VERSION ""

NS_ :

BS_:

BU_:

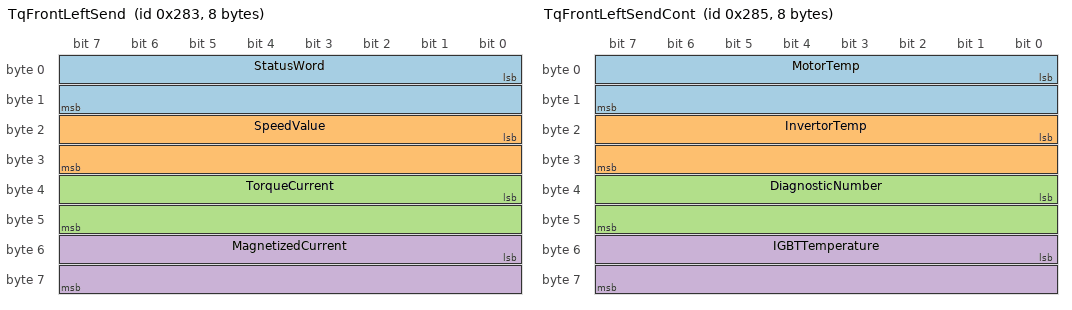
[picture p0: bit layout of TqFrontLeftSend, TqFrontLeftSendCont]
BO_ 643 TqFrontLeftSend: 8 Vector__XXX
 SG_ StatusWord : 0|16@1+ (1,0) [0|1] "Status Word" Vector__XXX
 SG_ SpeedValue : 16|16@1- (0.01,0) [0|5000] "1/rpm" Vector__XXX
 SG_ TorqueCurrent : 32|16@1- (0.01,0) [0|5000] "Iq" Vector__XXX
 SG_ MagnetizedCurrent : 48|16@1- (0.01,0) [0|5000] "Id" Vector__XXX

BO_ 645 TqFrontLeftSendCont: 8 Vector__XXX
 SG_ MotorTemp : 0|16@1- (0.1,0) [0|500] "C" Vector__XXX
 SG_ InvertorTemp : 16|16@1- (0.1,0) [0|500] "C" Vector__XXX
 SG_ DiagnosticNumber : 32|16@1+ (1,0) [0|20] "" Vector__XXX
 SG_ IGBTTemperature : 48|16@1- (0.1,0) [0|500] "C" Vector__XXX

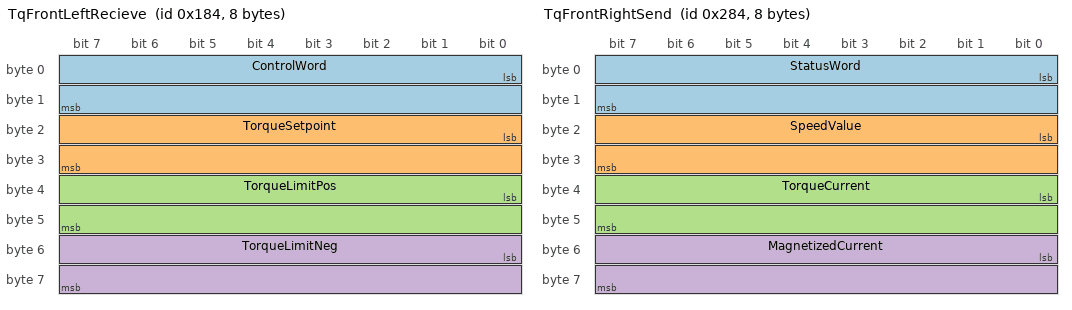
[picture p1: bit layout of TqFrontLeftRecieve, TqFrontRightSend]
BO_ 388 TqFrontLeftRecieve: 8 Vector__XXX
 SG_ ControlWord : 0|16@1+ (1,0) [0|10] "" Vector__XXX
 SG_ TorqueSetpoint : 16|16@1+ (0.01,0) [0|30] "Nm" Vector__XXX
 SG_ TorqueLimitPos : 32|16@1+ (0.01,0) [0|30] "Nm" Vector__XXX
 SG_ TorqueLimitNeg : 48|16@1+ (0.01,0) [0|30] "Nm" Vector__XXX

BO_ 644 TqFrontRightSend: 8 Vector__XXX
 SG_ StatusWord : 0|16@1+ (1,0) [0|1] "Status Word" Vector__XXX
 SG_ SpeedValue : 16|16@1- (0.01,0) [0|5000] "1/rpm" Vector__XXX
 SG_ TorqueCurrent : 32|16@1- (0.01,0) [0|5000] "Iq" Vector__XXX
 SG_ MagnetizedCurrent : 48|16@1- (0.01,0) [0|5000] "Id" Vector__XXX

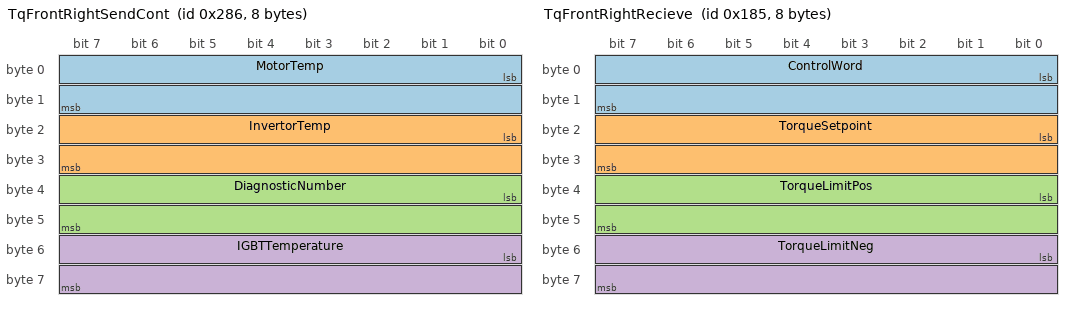
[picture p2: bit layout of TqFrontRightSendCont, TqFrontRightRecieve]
BO_ 646 TqFrontRightSendCont: 8 Vector__XXX
 SG_ MotorTemp : 0|16@1- (0.1,0) [0|500] "C" Vector__XXX
 SG_ InvertorTemp : 16|16@1- (0.1,0) [0|500] "C" Vector__XXX
 SG_ DiagnosticNumber : 32|16@1+ (1,0) [0|20] "" Vector__XXX
 SG_ IGBTTemperature : 48|16@1- (0.1,0) [0|500] "C" Vector__XXX

BO_ 389 TqFrontRightRecieve: 8 Vector__XXX
 SG_ ControlWord : 0|16@1+ (1,0) [0|10] "" Vector__XXX
 SG_ TorqueSetpoint : 16|16@1+ (0.01,0) [0|30] "Nm" Vector__XXX
 SG_ TorqueLimitPos : 32|16@1+ (0.01,0) [0|30] "Nm" Vector__XXX
 SG_ TorqueLimitNeg : 48|16@1+ (0.01,0) [0|30] "Nm" Vector__XXX

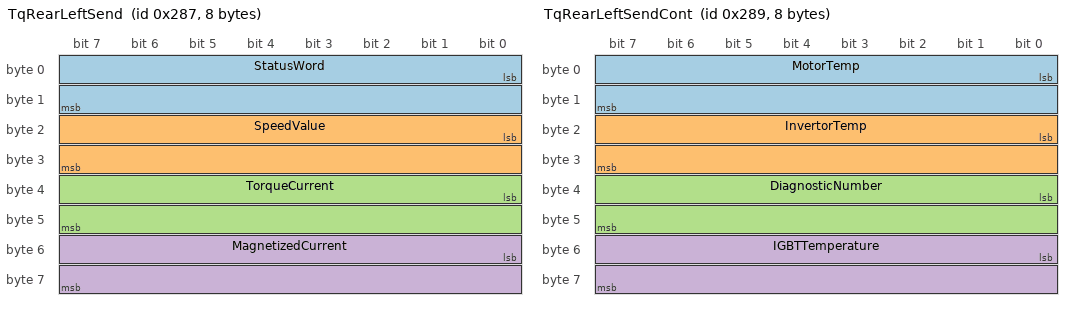
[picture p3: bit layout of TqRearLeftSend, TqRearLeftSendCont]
BO_ 647 TqRearLeftSend: 8 Vector__XXX
 SG_ StatusWord : 0|16@1+ (1,0) [0|1] "Status Word" Vector__XXX
 SG_ SpeedValue : 16|16@1- (0.01,0) [0|5000] "1/rpm" Vector__XXX
 SG_ TorqueCurrent : 32|16@1- (0.01,0) [0|5000] "Iq" Vector__XXX
 SG_ MagnetizedCurrent : 48|16@1- (0.01,0) [0|5000] "Id" Vector__XXX

BO_ 649 TqRearLeftSendCont: 8 Vector__XXX
 SG_ MotorTemp : 0|16@1- (0.1,0) [0|500] "C" Vector__XXX
 SG_ InvertorTemp : 16|16@1- (0.1,0) [0|500] "C" Vector__XXX
 SG_ DiagnosticNumber : 32|16@1+ (1,0) [0|20] "" Vector__XXX
 SG_ IGBTTemperature : 48|16@1- (0.1,0) [0|500] "C" Vector__XXX

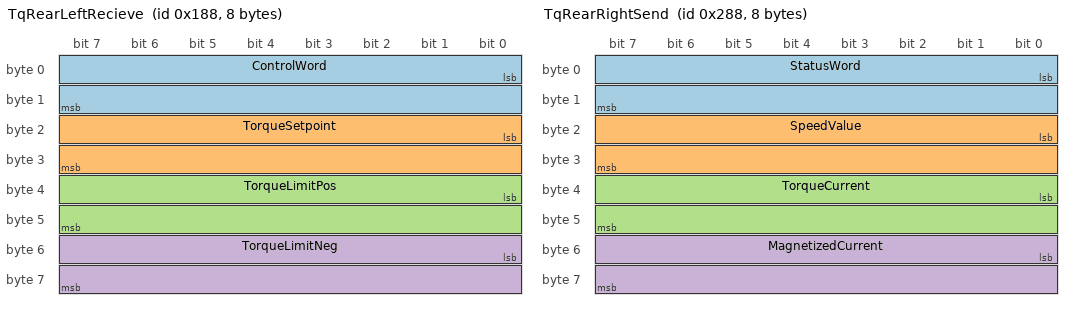
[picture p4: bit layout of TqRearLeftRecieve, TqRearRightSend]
BO_ 392 TqRearLeftRecieve: 8 Vector__XXX
 SG_ ControlWord : 0|16@1+ (1,0) [0|10] "" Vector__XXX
 SG_ TorqueSetpoint : 16|16@1+ (0.01,0) [0|30] "Nm" Vector__XXX
 SG_ TorqueLimitPos : 32|16@1+ (0.01,0) [0|30] "Nm" Vector__XXX
 SG_ TorqueLimitNeg : 48|16@1+ (0.01,0) [0|30] "Nm" Vector__XXX

BO_ 648 TqRearRightSend: 8 Vector__XXX
 SG_ StatusWord : 0|16@1+ (1,0) [0|1] "Status Word" Vector__XXX
 SG_ SpeedValue : 16|16@1- (0.01,0) [0|5000] "1/rpm" Vector__XXX
 SG_ TorqueCurrent : 32|16@1- (0.01,0) [0|5000] "Iq" Vector__XXX
 SG_ MagnetizedCurrent : 48|16@1- (0.01,0) [0|5000] "Id" Vector__XXX

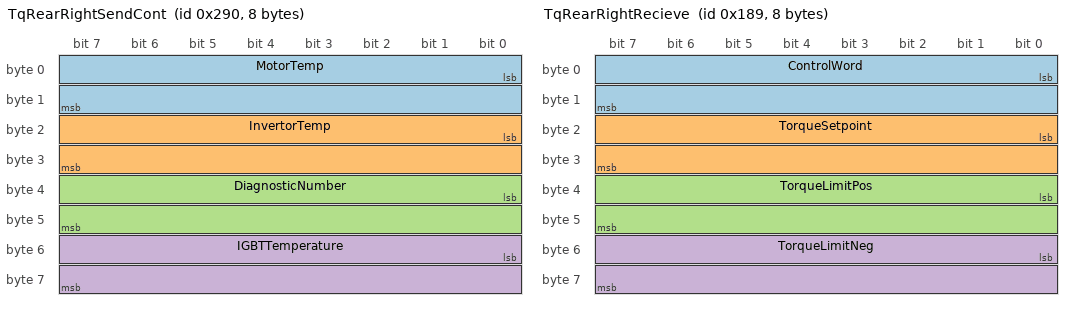
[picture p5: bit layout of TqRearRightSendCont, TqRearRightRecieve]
BO_ 656 TqRearRightSendCont: 8 Vector__XXX
 SG_ MotorTemp : 0|16@1- (0.1,0) [0|500] "C" Vector__XXX
 SG_ InvertorTemp : 16|16@1- (0.1,0) [0|500] "C" Vector__XXX
 SG_ DiagnosticNumber : 32|16@1+ (1,0) [0|20] "" Vector__XXX
 SG_ IGBTTemperature : 48|16@1- (0.1,0) [0|500] "C" Vector__XXX

BO_ 393 TqRearRightRecieve: 8 Vector__XXX
 SG_ ControlWord : 0|16@1+ (1,0) [0|10] "" Vector__XXX
 SG_ TorqueSetpoint : 16|16@1+ (0.01,0) [0|30] "Nm" Vector__XXX
 SG_ TorqueLimitPos : 32|16@1+ (0.01,0) [0|30] "Nm" Vector__XXX
 SG_ TorqueLimitNeg : 48|16@1+ (0.01,0) [0|30] "Nm" Vector__XXX

CM_ BO_ 643 "FreeCAN Torque Front Left MCM Send";
CM_ SG_ 643 StatusWord "Formula Student Status Recieve ";
CM_ BO_ 645 "FreeCAN Torque Front Left MCM Send";
CM_ SG_ 645 MotorTemp "0,1 C";
CM_ SG_ 645 InvertorTemp "0,1 C";
CM_ SG_ 645 DiagnosticNumber "Diagnostic Numbers";
CM_ SG_ 645 IGBTTemperature "0,1 C";
CM_ BO_ 388 "FreeCAN Torque Front Left MCM Recieve";
CM_ SG_ 388 ControlWord "Control Word";
CM_ SG_ 388 TorqueSetpoint "Torque Setpoint";
CM_ SG_ 388 TorqueLimitPos "Torque Limitation Positive";
CM_ SG_ 388 TorqueLimitNeg "Torque Limitation Negative";
BA_DEF_ SG_  "SPN" INT 0 524287;
BA_DEF_ BO_  "VFrameFormat" ENUM  "StandardCAN","ExtendedCAN","reserved","J1939PG";
BA_DEF_  "DatabaseVersion" STRING ;
BA_DEF_  "BusType" STRING ;
BA_DEF_  "ProtocolType" STRING ;
BA_DEF_  "DatabaseCompiler" STRING ;
BA_DEF_DEF_  "SPN" 0;
BA_DEF_DEF_  "VFrameFormat" "J1939PG";
BA_DEF_DEF_  "DatabaseVersion" "DEMO PLUS";
BA_DEF_DEF_  "BusType" "";
BA_DEF_DEF_  "ProtocolType" "";
BA_DEF_DEF_  "DatabaseCompiler" "";
BA_ "ProtocolType" "J1939";
BA_ "BusType" "CAN";
BA_ "DatabaseCompiler" "CSS ELECTRONICS (WWW.CSSELECTRONICS.COM)";
BA_ "DatabaseVersion" "1.0.0";
BA_ "SPN" SG_ 2364540158 EngineSpeed 190;
